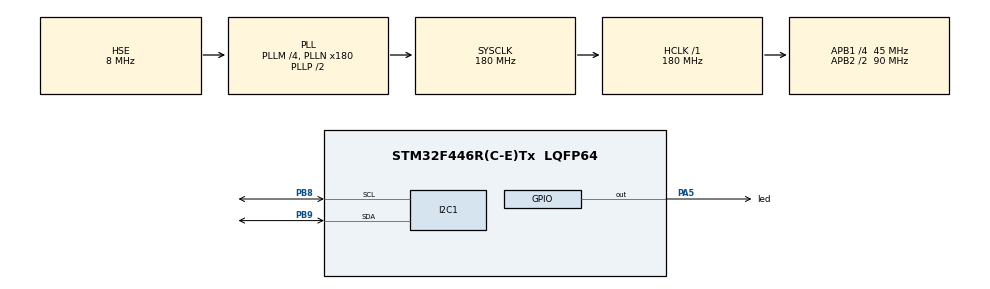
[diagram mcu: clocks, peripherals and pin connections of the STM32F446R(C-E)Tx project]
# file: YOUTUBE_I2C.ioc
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I2C1.I2C_Mode=I2C_Fast
Mcu.Family=STM32F4
Mcu.Name=STM32F446R(C-E)Tx
Mcu.Package=LQFP64
NVIC.PriorityGroup=NVIC_PRIORITYGROUP_0
PA5.GPIO_Label=led
PA5.Signal=GPIO_Output
PB8.Mode=I2C
PB8.Signal=I2C1_SCL
PB9.Mode=I2C
PB9.Signal=I2C1_SDA
PC14-OSC32_IN.Mode=LSE-External-Oscillator
PC14-OSC32_IN.Signal=RCC_OSC32_IN
PC15-OSC32_OUT.Mode=LSE-External-Oscillator
PC15-OSC32_OUT.Signal=RCC_OSC32_OUT
PH0-OSC_IN.Mode=HSE-External-Oscillator
PH0-OSC_IN.Signal=RCC_OSC_IN
PH1-OSC_OUT.Mode=HSE-External-Oscillator
PH1-OSC_OUT.Signal=RCC_OSC_OUT
ProjectManager.HeapSize=0x200
ProjectManager.StackSize=0x400
ProjectManager.TargetToolchain=MDK-ARM V5.27
RCC.AHBFreq_Value=180000000
RCC.APB1CLKDivider=RCC_HCLK_DIV4
RCC.APB1Freq_Value=45000000
RCC.APB1TimFreq_Value=90000000
RCC.APB2CLKDivider=RCC_HCLK_DIV2
RCC.APB2Freq_Value=90000000
RCC.APB2TimFreq_Value=180000000
RCC.CortexFreq_Value=180000000
RCC.FLatency-AdvancedSettings=FLASH_LATENCY_5
RCC.HCLKFreq_Value=180000000
RCC.HSE_VALUE=8000000
RCC.HSI_VALUE=16000000
RCC.PLLM=4
RCC.PLLN=180
RCC.PLLSourceVirtual=RCC_PLLSOURCE_HSE
RCC.SYSCLKFreq_VALUE=180000000
RCC.SYSCLKSource=RCC_SYSCLKSOURCE_PLLCLK
RCC.USBFreq_Value=180000000
RCC.VCOOutputFreq_Value=360000000
board=NUCLEO-F446RE

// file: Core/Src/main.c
/* USER CODE BEGIN Header */
/**
  ******************************************************************************
  * @file           : main.c
  * @brief          : Main program body
  ******************************************************************************
  * @attention
  *
  * <h2><center>&copy; Copyright (c) 2021 STMicroelectronics.
  * All rights reserved.</center></h2>
  *
  * This software component is licensed by ST under BSD 3-Clause license,
  * the "License"; You may not use this file except in compliance with the
  * License. You may obtain a copy of the License at:
  *                        opensource.org/licenses/BSD-3-Clause
  *
  ******************************************************************************
  */
/* USER CODE END Header */
#include "main.h"

/* USER CODE BEGIN PD */
#define DeviceAddress   0x68
#define Sec_Address     0x00
#define Min_Address     0x01
#define Hour_Address    0x02
/* USER CODE END PD */

I2C_HandleTypeDef hi2c1;

/* USER CODE BEGIN PV */

uint8_t buffer[2];
uint8_t Seconds,Minutes,Hours;
/* USER CODE END PV */

void SystemClock_Config(void);
static void MX_GPIO_Init(void);
static void MX_I2C1_Init(void);

int main(void)
{

  /* MCU Configuration--------------------------------------------------------*/

  /* Reset of all peripherals, Initializes the Flash interface and the Systick. */
  HAL_Init();

  /* Configure the system clock */
  SystemClock_Config();

  /* Initialize all configured peripherals */
  MX_GPIO_Init();
  MX_I2C1_Init();
  /* USER CODE BEGIN 2 */
	if(HAL_I2C_IsDeviceReady(&hi2c1,DeviceAddress<<1,2, 100)==HAL_OK)
	{
		HAL_GPIO_WritePin(GPIOA,GPIO_PIN_5,GPIO_PIN_SET);
		HAL_Delay(2000);
		HAL_GPIO_WritePin(GPIOA,GPIO_PIN_5,GPIO_PIN_RESET);
	}

	buffer[0]=Sec_Address;
	buffer[1]=0x57;
	HAL_I2C_Master_Transmit(&hi2c1,(DeviceAddress<<1)|0x01,buffer,2,100);

	buffer[0]=Min_Address;
	buffer[1]=0x59;
	HAL_I2C_Master_Transmit(&hi2c1,(DeviceAddress<<1)|0x01,buffer,2,100);

	buffer[0]=Hour_Address;
	buffer[1]=0x12;
	HAL_I2C_Master_Transmit(&hi2c1,(DeviceAddress<<1)|0x01,buffer,2,100);

  /* USER CODE END 2 */

  /* Infinite loop */
  while (1)
  {

    /* USER CODE BEGIN 3 */
		buffer[0]=Sec_Address;
		HAL_I2C_Master_Transmit(&hi2c1,DeviceAddress<<1,&buffer[0],1,100);
		HAL_I2C_Master_Receive(&hi2c1,DeviceAddress<<1,&Seconds,1,100);

		buffer[0]=Min_Address;
		HAL_I2C_Master_Transmit(&hi2c1,DeviceAddress<<1,&buffer[0],1,100);
		HAL_I2C_Master_Receive(&hi2c1,DeviceAddress<<1,&Minutes,1,100);

		buffer[0]=Hour_Address;
		HAL_I2C_Master_Transmit(&hi2c1,DeviceAddress<<1,&buffer[0],1,100);
		HAL_I2C_Master_Receive(&hi2c1,DeviceAddress<<1,&Hours,1,100);

  }
  /* USER CODE END 3 */
}

void SystemClock_Config(void)
{
  RCC_OscInitTypeDef RCC_OscInitStruct = {0};
  RCC_ClkInitTypeDef RCC_ClkInitStruct = {0};

  /** Configure the main internal regulator output voltage
  */
  __HAL_RCC_PWR_CLK_ENABLE();
  __HAL_PWR_VOLTAGESCALING_CONFIG(PWR_REGULATOR_VOLTAGE_SCALE1);
  /** Initializes the RCC Oscillators according to the specified parameters
  * in the RCC_OscInitTypeDef structure.
  */
  RCC_OscInitStruct.OscillatorType = RCC_OSCILLATORTYPE_HSE;
  RCC_OscInitStruct.HSEState = RCC_HSE_ON;
  RCC_OscInitStruct.PLL.PLLState = RCC_PLL_ON;
  RCC_OscInitStruct.PLL.PLLSource = RCC_PLLSOURCE_HSE;
  RCC_OscInitStruct.PLL.PLLM = 4;
  RCC_OscInitStruct.PLL.PLLN = 180;
  RCC_OscInitStruct.PLL.PLLP = RCC_PLLP_DIV2;
  RCC_OscInitStruct.PLL.PLLQ = 2;
  RCC_OscInitStruct.PLL.PLLR = 2;
  if (HAL_RCC_OscConfig(&RCC_OscInitStruct) != HAL_OK)
  {
    Error_Handler();
  }
  /** Activate the Over-Drive mode
  */
  if (HAL_PWREx_EnableOverDrive() != HAL_OK)
  {
    Error_Handler();
  }
  /** Initializes the CPU, AHB and APB buses clocks
  */
  RCC_ClkInitStruct.ClockType = RCC_CLOCKTYPE_HCLK|RCC_CLOCKTYPE_SYSCLK
                              |RCC_CLOCKTYPE_PCLK1|RCC_CLOCKTYPE_PCLK2;
  RCC_ClkInitStruct.SYSCLKSource = RCC_SYSCLKSOURCE_PLLCLK;
  RCC_ClkInitStruct.AHBCLKDivider = RCC_SYSCLK_DIV1;
  RCC_ClkInitStruct.APB1CLKDivider = RCC_HCLK_DIV4;
  RCC_ClkInitStruct.APB2CLKDivider = RCC_HCLK_DIV2;

  if (HAL_RCC_ClockConfig(&RCC_ClkInitStruct, FLASH_LATENCY_5) != HAL_OK)
  {
    Error_Handler();
  }
}

static void MX_I2C1_Init(void)
{

  hi2c1.Instance = I2C1;
  hi2c1.Init.ClockSpeed = 400000;
  hi2c1.Init.DutyCycle = I2C_DUTYCYCLE_2;
  hi2c1.Init.OwnAddress1 = 0;
  hi2c1.Init.AddressingMode = I2C_ADDRESSINGMODE_7BIT;
  hi2c1.Init.DualAddressMode = I2C_DUALADDRESS_DISABLE;
  hi2c1.Init.OwnAddress2 = 0;
  hi2c1.Init.GeneralCallMode = I2C_GENERALCALL_DISABLE;
  hi2c1.Init.NoStretchMode = I2C_NOSTRETCH_DISABLE;
  if (HAL_I2C_Init(&hi2c1) != HAL_OK)
  {
    Error_Handler();
  }

}

static void MX_GPIO_Init(void)
{
  GPIO_InitTypeDef GPIO_InitStruct = {0};

  /* GPIO Ports Clock Enable */
  __HAL_RCC_GPIOC_CLK_ENABLE();
  __HAL_RCC_GPIOH_CLK_ENABLE();
  __HAL_RCC_GPIOA_CLK_ENABLE();
  __HAL_RCC_GPIOB_CLK_ENABLE();

  /*Configure GPIO pin Output Level */
  HAL_GPIO_WritePin(led_GPIO_Port, led_Pin, GPIO_PIN_RESET);

  /*Configure GPIO pin : led_Pin */
  GPIO_InitStruct.Pin = led_Pin;
  GPIO_InitStruct.Mode = GPIO_MODE_OUTPUT_PP;
  GPIO_InitStruct.Pull = GPIO_NOPULL;
  GPIO_InitStruct.Speed = GPIO_SPEED_FREQ_LOW;
  HAL_GPIO_Init(led_GPIO_Port, &GPIO_InitStruct);

}

void Error_Handler(void)
{
  __disable_irq();
  while (1)
  {
  }
}

/************************ (C) COPYRIGHT STMicroelectronics *****END OF FILE****/
